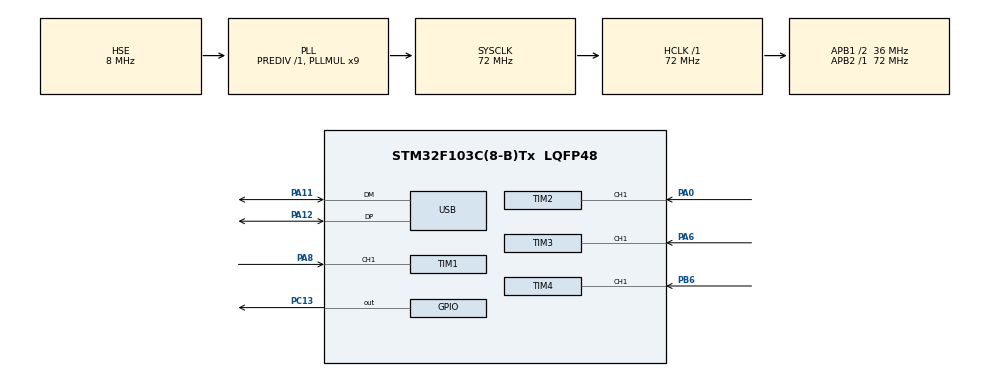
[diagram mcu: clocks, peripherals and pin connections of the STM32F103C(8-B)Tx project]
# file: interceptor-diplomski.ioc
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Mcu.Family=STM32F1
Mcu.Name=STM32F103C(8-B)Tx
Mcu.Package=LQFP48
NVIC.PriorityGroup=NVIC_PRIORITYGROUP_4
NVIC.TIM1_CC_IRQn=true\:0\:0\:false\:false\:true\:true\:true\:true
NVIC.TIM2_IRQn=true\:0\:0\:false\:false\:true\:true\:true\:true
NVIC.TIM3_IRQn=true\:0\:0\:false\:false\:true\:true\:true\:true
NVIC.TIM4_IRQn=true\:0\:0\:false\:false\:true\:true\:true\:true
NVIC.USB_LP_CAN1_RX0_IRQn=true\:0\:0\:false\:false\:true\:false\:true\:true
PA0-WKUP.Signal=S_TIM2_CH1_ETR
PA11.Mode=Device
PA11.Signal=USB_DM
PA12.Mode=Device
PA12.Signal=USB_DP
PA13.Mode=Serial_Wire
PA13.Signal=SYS_JTMS-SWDIO
PA14.Mode=Serial_Wire
PA14.Signal=SYS_JTCK-SWCLK
PA6.Signal=S_TIM3_CH1
PA8.Signal=S_TIM1_CH1
PB6.Signal=S_TIM4_CH1
PC13-TAMPER-RTC.Signal=GPIO_Output
PD0-OSC_IN.Mode=HSE-External-Oscillator
PD0-OSC_IN.Signal=RCC_OSC_IN
PD1-OSC_OUT.Mode=HSE-External-Oscillator
PD1-OSC_OUT.Signal=RCC_OSC_OUT
ProjectManager.HeapSize=0x200
ProjectManager.StackSize=0x400
ProjectManager.TargetToolchain=CMake
RCC.AHBFreq_Value=72000000
RCC.APB1CLKDivider=RCC_HCLK_DIV2
RCC.APB1Freq_Value=36000000
RCC.APB1TimFreq_Value=72000000
RCC.APB2Freq_Value=72000000
RCC.APB2TimFreq_Value=72000000
RCC.HCLKFreq_Value=72000000
RCC.PLLMUL=RCC_PLL_MUL9
RCC.PLLSourceVirtual=RCC_PLLSOURCE_HSE
RCC.SYSCLKFreq_VALUE=72000000
RCC.SYSCLKSource=RCC_SYSCLKSOURCE_PLLCLK
RCC.USBFreq_Value=48000000
RCC.USBPrescaler=RCC_USBCLKSOURCE_PLL_DIV1_5
SH.S_TIM1_CH1.0=TIM1_CH1,PWM_Input_1
SH.S_TIM2_CH1_ETR.0=TIM2_CH1,PWM_Input_1
SH.S_TIM3_CH1.0=TIM3_CH1,PWM_Input_1
SH.S_TIM4_CH1.0=TIM4_CH1,PWM_Input_1
TIM1.Prescaler=71
TIM2.Prescaler=71
TIM3.Prescaler=71
TIM4.Prescaler=71
USB_DEVICE.CLASS_NAME_FS=CDC
USB_DEVICE.VirtualMode=Cdc
USB_DEVICE.VirtualModeFS=Cdc_FS
VP_TIM1_VS_ClockSourceINT.Mode=Internal
VP_TIM2_VS_ClockSourceINT.Mode=Internal
VP_TIM3_VS_ClockSourceINT.Mode=Internal
VP_TIM4_VS_ClockSourceINT.Mode=Internal
VP_USB_DEVICE_VS_USB_DEVICE_CDC_FS.Mode=CDC_FS
board=custom

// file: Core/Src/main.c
/* USER CODE BEGIN Header */
/**
 ******************************************************************************
 * @file           : main.c
 * @brief          : Main program body
 ******************************************************************************
 * @attention
 *
 * Copyright (c) 2024 STMicroelectronics.
 * All rights reserved.
 *
 * This software is licensed under terms that can be found in the LICENSE file
 * in the root directory of this software component.
 * If no LICENSE file comes with this software, it is provided AS-IS.
 *
 ******************************************************************************
 */
/* USER CODE END Header */
#include "main.h"
#include "usb_device.h"

/* USER CODE BEGIN Includes */

#include "entrypoint.h"

/* USER CODE END Includes */

TIM_HandleTypeDef htim1;
TIM_HandleTypeDef htim2;
TIM_HandleTypeDef htim3;
TIM_HandleTypeDef htim4;

void SystemClock_Config(void);
static void MX_GPIO_Init(void);
static void MX_TIM1_Init(void);
static void MX_TIM2_Init(void);
static void MX_TIM3_Init(void);
static void MX_TIM4_Init(void);

int main(void) {

  /* MCU Configuration--------------------------------------------------------*/

  /* Reset of all peripherals, Initializes the Flash interface and the Systick.
   */
  HAL_Init();

  /* Configure the system clock */
  SystemClock_Config();

  /* Initialize all configured peripherals */
  MX_GPIO_Init();
  MX_USB_DEVICE_Init();
  MX_TIM1_Init();
  MX_TIM2_Init();
  MX_TIM3_Init();
  MX_TIM4_Init();

  /* Infinite loop */
  /* USER CODE BEGIN WHILE */
  CORE_Entrypoint(&htim1, &htim2, &htim3, &htim4);
  /* USER CODE END WHILE */

}

void SystemClock_Config(void) {
  RCC_OscInitTypeDef RCC_OscInitStruct = {0};
  RCC_ClkInitTypeDef RCC_ClkInitStruct = {0};
  RCC_PeriphCLKInitTypeDef PeriphClkInit = {0};

  /** Initializes the RCC Oscillators according to the specified parameters
   * in the RCC_OscInitTypeDef structure.
   */
  RCC_OscInitStruct.OscillatorType = RCC_OSCILLATORTYPE_HSE;
  RCC_OscInitStruct.HSEState = RCC_HSE_ON;
  RCC_OscInitStruct.HSEPredivValue = RCC_HSE_PREDIV_DIV1;
  RCC_OscInitStruct.HSIState = RCC_HSI_ON;
  RCC_OscInitStruct.PLL.PLLState = RCC_PLL_ON;
  RCC_OscInitStruct.PLL.PLLSource = RCC_PLLSOURCE_HSE;
  RCC_OscInitStruct.PLL.PLLMUL = RCC_PLL_MUL9;
  if (HAL_RCC_OscConfig(&RCC_OscInitStruct) != HAL_OK) {
    Error_Handler();
  }

  /** Initializes the CPU, AHB and APB buses clocks
   */
  RCC_ClkInitStruct.ClockType = RCC_CLOCKTYPE_HCLK | RCC_CLOCKTYPE_SYSCLK |
                                RCC_CLOCKTYPE_PCLK1 | RCC_CLOCKTYPE_PCLK2;
  RCC_ClkInitStruct.SYSCLKSource = RCC_SYSCLKSOURCE_PLLCLK;
  RCC_ClkInitStruct.AHBCLKDivider = RCC_SYSCLK_DIV1;
  RCC_ClkInitStruct.APB1CLKDivider = RCC_HCLK_DIV2;
  RCC_ClkInitStruct.APB2CLKDivider = RCC_HCLK_DIV1;

  if (HAL_RCC_ClockConfig(&RCC_ClkInitStruct, FLASH_LATENCY_2) != HAL_OK) {
    Error_Handler();
  }
  PeriphClkInit.PeriphClockSelection = RCC_PERIPHCLK_USB;
  PeriphClkInit.UsbClockSelection = RCC_USBCLKSOURCE_PLL_DIV1_5;
  if (HAL_RCCEx_PeriphCLKConfig(&PeriphClkInit) != HAL_OK) {
    Error_Handler();
  }
}

static void MX_TIM1_Init(void) {

  TIM_ClockConfigTypeDef sClockSourceConfig = {0};
  TIM_SlaveConfigTypeDef sSlaveConfig = {0};
  TIM_IC_InitTypeDef sConfigIC = {0};
  TIM_MasterConfigTypeDef sMasterConfig = {0};

  htim1.Instance = TIM1;
  htim1.Init.Prescaler = 9;
  htim1.Init.CounterMode = TIM_COUNTERMODE_UP;
  htim1.Init.Period = 65535;
  htim1.Init.ClockDivision = TIM_CLOCKDIVISION_DIV1;
  htim1.Init.RepetitionCounter = 0;
  htim1.Init.AutoReloadPreload = TIM_AUTORELOAD_PRELOAD_DISABLE;
  if (HAL_TIM_Base_Init(&htim1) != HAL_OK) {
    Error_Handler();
  }
  sClockSourceConfig.ClockSource = TIM_CLOCKSOURCE_INTERNAL;
  if (HAL_TIM_ConfigClockSource(&htim1, &sClockSourceConfig) != HAL_OK) {
    Error_Handler();
  }
  if (HAL_TIM_IC_Init(&htim1) != HAL_OK) {
    Error_Handler();
  }
  sSlaveConfig.SlaveMode = TIM_SLAVEMODE_RESET;
  sSlaveConfig.InputTrigger = TIM_TS_TI1FP1;
  sSlaveConfig.TriggerPolarity = TIM_INPUTCHANNELPOLARITY_RISING;
  sSlaveConfig.TriggerPrescaler = TIM_ICPSC_DIV1;
  sSlaveConfig.TriggerFilter = 0;
  if (HAL_TIM_SlaveConfigSynchro(&htim1, &sSlaveConfig) != HAL_OK) {
    Error_Handler();
  }
  sConfigIC.ICPolarity = TIM_INPUTCHANNELPOLARITY_RISING;
  sConfigIC.ICSelection = TIM_ICSELECTION_DIRECTTI;
  sConfigIC.ICPrescaler = TIM_ICPSC_DIV1;
  sConfigIC.ICFilter = 0;
  if (HAL_TIM_IC_ConfigChannel(&htim1, &sConfigIC, TIM_CHANNEL_1) != HAL_OK) {
    Error_Handler();
  }
  sConfigIC.ICPolarity = TIM_INPUTCHANNELPOLARITY_FALLING;
  sConfigIC.ICSelection = TIM_ICSELECTION_INDIRECTTI;
  if (HAL_TIM_IC_ConfigChannel(&htim1, &sConfigIC, TIM_CHANNEL_2) != HAL_OK) {
    Error_Handler();
  }
  sMasterConfig.MasterOutputTrigger = TIM_TRGO_RESET;
  sMasterConfig.MasterSlaveMode = TIM_MASTERSLAVEMODE_DISABLE;
  if (HAL_TIMEx_MasterConfigSynchronization(&htim1, &sMasterConfig) != HAL_OK) {
    Error_Handler();
  }
  /* USER CODE BEGIN TIM1_Init 2 */

  HAL_TIM_IC_Start_IT(&htim1, TIM_CHANNEL_1);
  HAL_TIM_IC_Start(&htim1, TIM_CHANNEL_2);

  /* USER CODE END TIM1_Init 2 */
}

static void MX_TIM2_Init(void) {

  TIM_ClockConfigTypeDef sClockSourceConfig = {0};
  TIM_SlaveConfigTypeDef sSlaveConfig = {0};
  TIM_IC_InitTypeDef sConfigIC = {0};
  TIM_MasterConfigTypeDef sMasterConfig = {0};

  htim2.Instance = TIM2;
  htim2.Init.Prescaler = 9;
  htim2.Init.CounterMode = TIM_COUNTERMODE_UP;
  htim2.Init.Period = 65535;
  htim2.Init.ClockDivision = TIM_CLOCKDIVISION_DIV1;
  htim2.Init.AutoReloadPreload = TIM_AUTORELOAD_PRELOAD_DISABLE;
  if (HAL_TIM_Base_Init(&htim2) != HAL_OK) {
    Error_Handler();
  }
  sClockSourceConfig.ClockSource = TIM_CLOCKSOURCE_INTERNAL;
  if (HAL_TIM_ConfigClockSource(&htim2, &sClockSourceConfig) != HAL_OK) {
    Error_Handler();
  }
  if (HAL_TIM_IC_Init(&htim2) != HAL_OK) {
    Error_Handler();
  }
  sSlaveConfig.SlaveMode = TIM_SLAVEMODE_RESET;
  sSlaveConfig.InputTrigger = TIM_TS_TI1FP1;
  sSlaveConfig.TriggerPolarity = TIM_INPUTCHANNELPOLARITY_RISING;
  sSlaveConfig.TriggerPrescaler = TIM_ICPSC_DIV1;
  sSlaveConfig.TriggerFilter = 0;
  if (HAL_TIM_SlaveConfigSynchro(&htim2, &sSlaveConfig) != HAL_OK) {
    Error_Handler();
  }
  sConfigIC.ICPolarity = TIM_INPUTCHANNELPOLARITY_RISING;
  sConfigIC.ICSelection = TIM_ICSELECTION_DIRECTTI;
  sConfigIC.ICPrescaler = TIM_ICPSC_DIV1;
  sConfigIC.ICFilter = 0;
  if (HAL_TIM_IC_ConfigChannel(&htim2, &sConfigIC, TIM_CHANNEL_1) != HAL_OK) {
    Error_Handler();
  }
  sConfigIC.ICPolarity = TIM_INPUTCHANNELPOLARITY_FALLING;
  sConfigIC.ICSelection = TIM_ICSELECTION_INDIRECTTI;
  if (HAL_TIM_IC_ConfigChannel(&htim2, &sConfigIC, TIM_CHANNEL_2) != HAL_OK) {
    Error_Handler();
  }
  sMasterConfig.MasterOutputTrigger = TIM_TRGO_RESET;
  sMasterConfig.MasterSlaveMode = TIM_MASTERSLAVEMODE_DISABLE;
  if (HAL_TIMEx_MasterConfigSynchronization(&htim2, &sMasterConfig) != HAL_OK) {
    Error_Handler();
  }
  /* USER CODE BEGIN TIM2_Init 2 */

  HAL_TIM_IC_Start_IT(&htim2, TIM_CHANNEL_1);
  HAL_TIM_IC_Start(&htim2, TIM_CHANNEL_2);

  /* USER CODE END TIM2_Init 2 */
}

static void MX_TIM3_Init(void) {

  TIM_ClockConfigTypeDef sClockSourceConfig = {0};
  TIM_SlaveConfigTypeDef sSlaveConfig = {0};
  TIM_IC_InitTypeDef sConfigIC = {0};
  TIM_MasterConfigTypeDef sMasterConfig = {0};

  htim3.Instance = TIM3;
  htim3.Init.Prescaler = 9;
  htim3.Init.CounterMode = TIM_COUNTERMODE_UP;
  htim3.Init.Period = 65535;
  htim3.Init.ClockDivision = TIM_CLOCKDIVISION_DIV1;
  htim3.Init.AutoReloadPreload = TIM_AUTORELOAD_PRELOAD_DISABLE;
  if (HAL_TIM_Base_Init(&htim3) != HAL_OK) {
    Error_Handler();
  }
  sClockSourceConfig.ClockSource = TIM_CLOCKSOURCE_INTERNAL;
  if (HAL_TIM_ConfigClockSource(&htim3, &sClockSourceConfig) != HAL_OK) {
    Error_Handler();
  }
  if (HAL_TIM_IC_Init(&htim3) != HAL_OK) {
    Error_Handler();
  }
  sSlaveConfig.SlaveMode = TIM_SLAVEMODE_RESET;
  sSlaveConfig.InputTrigger = TIM_TS_TI1FP1;
  sSlaveConfig.TriggerPolarity = TIM_INPUTCHANNELPOLARITY_RISING;
  sSlaveConfig.TriggerPrescaler = TIM_ICPSC_DIV1;
  sSlaveConfig.TriggerFilter = 0;
  if (HAL_TIM_SlaveConfigSynchro(&htim3, &sSlaveConfig) != HAL_OK) {
    Error_Handler();
  }
  sConfigIC.ICPolarity = TIM_INPUTCHANNELPOLARITY_RISING;
  sConfigIC.ICSelection = TIM_ICSELECTION_DIRECTTI;
  sConfigIC.ICPrescaler = TIM_ICPSC_DIV1;
  sConfigIC.ICFilter = 0;
  if (HAL_TIM_IC_ConfigChannel(&htim3, &sConfigIC, TIM_CHANNEL_1) != HAL_OK) {
    Error_Handler();
  }
  sConfigIC.ICPolarity = TIM_INPUTCHANNELPOLARITY_FALLING;
  sConfigIC.ICSelection = TIM_ICSELECTION_INDIRECTTI;
  if (HAL_TIM_IC_ConfigChannel(&htim3, &sConfigIC, TIM_CHANNEL_2) != HAL_OK) {
    Error_Handler();
  }
  sMasterConfig.MasterOutputTrigger = TIM_TRGO_RESET;
  sMasterConfig.MasterSlaveMode = TIM_MASTERSLAVEMODE_DISABLE;
  if (HAL_TIMEx_MasterConfigSynchronization(&htim3, &sMasterConfig) != HAL_OK) {
    Error_Handler();
  }
  /* USER CODE BEGIN TIM3_Init 2 */

  HAL_TIM_IC_Start_IT(&htim3, TIM_CHANNEL_1);
  HAL_TIM_IC_Start(&htim3, TIM_CHANNEL_2);

  /* USER CODE END TIM3_Init 2 */
}

static void MX_TIM4_Init(void) {

  TIM_ClockConfigTypeDef sClockSourceConfig = {0};
  TIM_SlaveConfigTypeDef sSlaveConfig = {0};
  TIM_IC_InitTypeDef sConfigIC = {0};
  TIM_MasterConfigTypeDef sMasterConfig = {0};

  htim4.Instance = TIM4;
  htim4.Init.Prescaler = 9;
  htim4.Init.CounterMode = TIM_COUNTERMODE_UP;
  htim4.Init.Period = 65535;
  htim4.Init.ClockDivision = TIM_CLOCKDIVISION_DIV1;
  htim4.Init.AutoReloadPreload = TIM_AUTORELOAD_PRELOAD_DISABLE;
  if (HAL_TIM_Base_Init(&htim4) != HAL_OK) {
    Error_Handler();
  }
  sClockSourceConfig.ClockSource = TIM_CLOCKSOURCE_INTERNAL;
  if (HAL_TIM_ConfigClockSource(&htim4, &sClockSourceConfig) != HAL_OK) {
    Error_Handler();
  }
  if (HAL_TIM_IC_Init(&htim4) != HAL_OK) {
    Error_Handler();
  }
  sSlaveConfig.SlaveMode = TIM_SLAVEMODE_RESET;
  sSlaveConfig.InputTrigger = TIM_TS_TI1FP1;
  sSlaveConfig.TriggerPolarity = TIM_INPUTCHANNELPOLARITY_RISING;
  sSlaveConfig.TriggerPrescaler = TIM_ICPSC_DIV1;
  sSlaveConfig.TriggerFilter = 0;
  if (HAL_TIM_SlaveConfigSynchro(&htim4, &sSlaveConfig) != HAL_OK) {
    Error_Handler();
  }
  sConfigIC.ICPolarity = TIM_INPUTCHANNELPOLARITY_RISING;
  sConfigIC.ICSelection = TIM_ICSELECTION_DIRECTTI;
  sConfigIC.ICPrescaler = TIM_ICPSC_DIV1;
  sConfigIC.ICFilter = 0;
  if (HAL_TIM_IC_ConfigChannel(&htim4, &sConfigIC, TIM_CHANNEL_1) != HAL_OK) {
    Error_Handler();
  }
  sConfigIC.ICPolarity = TIM_INPUTCHANNELPOLARITY_FALLING;
  sConfigIC.ICSelection = TIM_ICSELECTION_INDIRECTTI;
  if (HAL_TIM_IC_ConfigChannel(&htim4, &sConfigIC, TIM_CHANNEL_2) != HAL_OK) {
    Error_Handler();
  }
  sMasterConfig.MasterOutputTrigger = TIM_TRGO_RESET;
  sMasterConfig.MasterSlaveMode = TIM_MASTERSLAVEMODE_DISABLE;
  if (HAL_TIMEx_MasterConfigSynchronization(&htim4, &sMasterConfig) != HAL_OK) {
    Error_Handler();
  }
  /* USER CODE BEGIN TIM4_Init 2 */

  HAL_TIM_IC_Start_IT(&htim4, TIM_CHANNEL_1);
  HAL_TIM_IC_Start(&htim4, TIM_CHANNEL_2);

  /* USER CODE END TIM4_Init 2 */
}

static void MX_GPIO_Init(void) {
  GPIO_InitTypeDef GPIO_InitStruct = {0};

  /* GPIO Ports Clock Enable */
  __HAL_RCC_GPIOC_CLK_ENABLE();
  __HAL_RCC_GPIOD_CLK_ENABLE();
  __HAL_RCC_GPIOA_CLK_ENABLE();
  __HAL_RCC_GPIOB_CLK_ENABLE();

  /*Configure GPIO pin Output Level */
  HAL_GPIO_WritePin(GPIOC, GPIO_PIN_13, GPIO_PIN_RESET);

  /*Configure GPIO pin : PC13 */
  GPIO_InitStruct.Pin = GPIO_PIN_13;
  GPIO_InitStruct.Mode = GPIO_MODE_OUTPUT_PP;
  GPIO_InitStruct.Pull = GPIO_NOPULL;
  GPIO_InitStruct.Speed = GPIO_SPEED_FREQ_LOW;
  HAL_GPIO_Init(GPIOC, &GPIO_InitStruct);

}

void Error_Handler(void) {
  __disable_irq();
  while (1) {
  }
}

#ifdef USE_FULL_ASSERT
/**
 * @brief  Reports the name of the source file and the source line number
 *         where the assert_param error has occurred.
 * @param  file: pointer to the source file name
 * @param  line: assert_param error line source number
 * @retval None
 */
void assert_failed(uint8_t *file, uint32_t line) {
  /* USER CODE BEGIN 6 */
  /* User can add his own implementation to report the file name and line
     number, ex: printf("Wrong parameters value: file %s on line %d\r\n", file,
     line) */
  /* USER CODE END 6 */
}
#endif /* USE_FULL_ASSERT */
